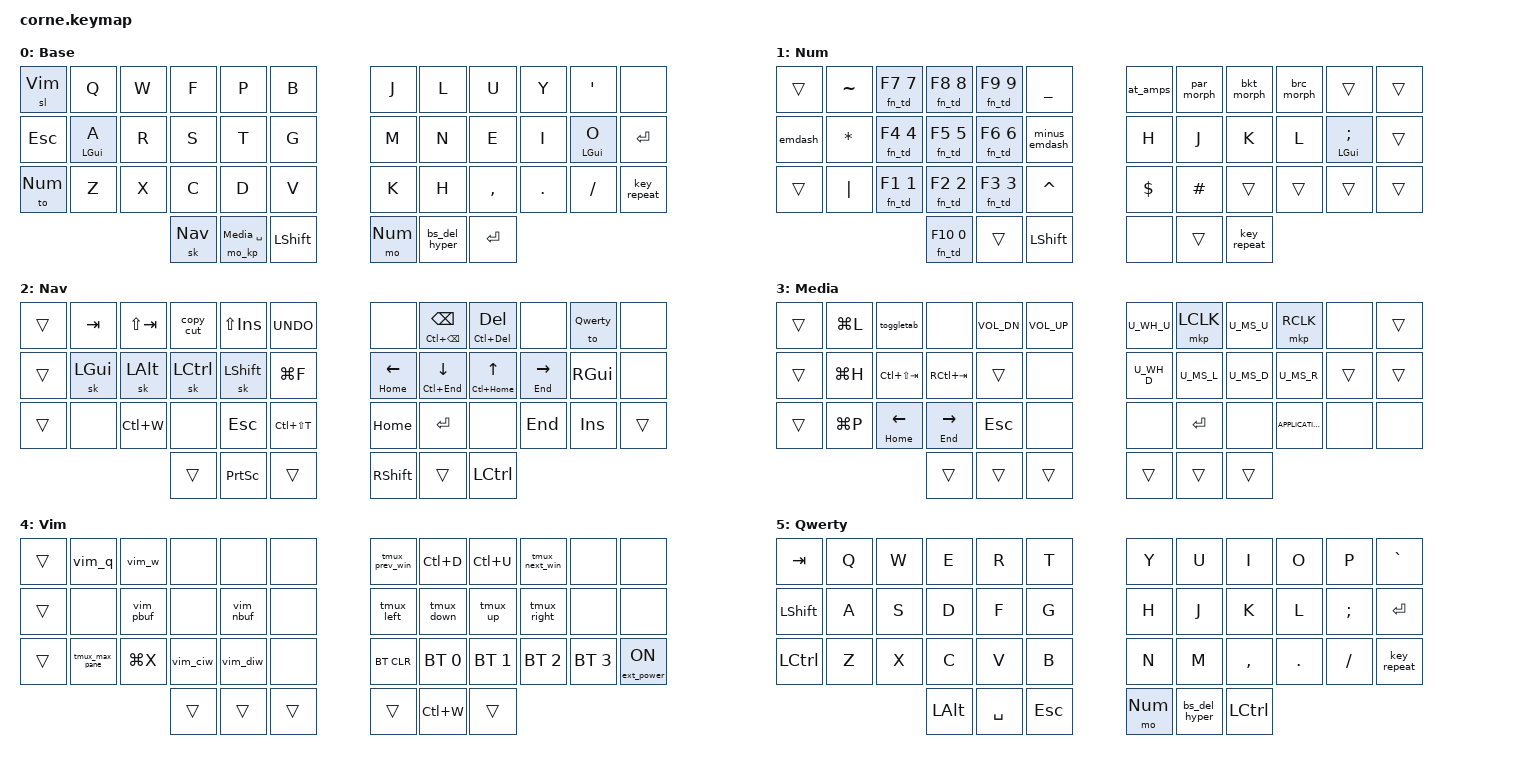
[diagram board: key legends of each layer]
#include <behaviors.dtsi>
#include <dt-bindings/zmk/keys.h>
#include <dt-bindings/zmk/bt.h>
#include <dt-bindings/zmk/mouse.h>
#include <dt-bindings/zmk/ext_power.h>
#include <dt-bindings/zmk/outputs.h>

#include "../zmk-nodefree-config/keypos_def/keypos_42keys.h"
#include "../zmk-nodefree-config/helper.h"

#define Base 0
#define Num 1
#define Nav 2
#define Media 3
#define Vim 4
#define Qwerty 5

#include "combos.dtsi"  // must be sourced after layer-shortcuts
#include "mouse.dtsi"

#define QUICK_TAP_MS 175

&sk {  // sticky-key config
    release-after-ms = <600>;  // release after 0.6s
    quick-release;             // no double capitalization when rolling keys
};

&sl {  // sticky-layer config
    ignore-modifiers;
};

&mt {
    flavor = "tap-preferred";
    tapping-term-ms = <220>;
    quick-tap-ms = <220>;              // repeat on tap-into-hold
    hold-trigger-key-positions = <0>;  // tap on interrupt
};

#define NAV_LEFT  &mt HOME     LEFT    // tap: left  | long-tap: beginning of line
#define NAV_RIGHT &mt END      RIGHT   // tap: right | long-tap: end       of line
#define NAV_UP    &mt LC(HOME) UP      // tap: up    | long-tap: beginning of document
#define NAV_DOWN  &mt LC(END)  DOWN    // tap: down  | long-tap: end       of document
#define NAV_BSPC  &mt LC(BSPC) BSPC    // tap: bspc  | long-tap: delete word backward
#define NAV_DEL   &mt LC(DEL)  DEL     // tap: del   | long-tap: delete word forward

&lt {
    flavor = "balanced";
    tapping-term-ms = <200>;
    quick_tap_ms = <QUICK_TAP_MS>;
};

&caps_word {  // mods deactivate caps-word, requires PR #1441
    /delete-property/ ignore-modifiers;
};


/* Homerow mods */

#define KEYS_L LT0 LT1 LT2 LT3 LT4 LM0 LM1 LM2 LM3 LM4 LB0 LB1 LB2 LB3 LB4  // left-hand keys
#define KEYS_R RT0 RT1 RT2 RT3 RT4 RM0 RM1 RM2 RM3 RM4 RB0 RB1 RB2 RB3 RB4  // right-hand keys
#define THUMBS LH2 LH1 LH0 RH0 RH1 RH2                                      // thumb keys

ZMK_BEHAVIOR(hml, hold_tap,  // left-hand HRMs
    flavor = "balanced";
    tapping-term-ms = <280>;
    quick-tap-ms = <QUICK_TAP_MS>;
    require-prior-idle-ms = <150>;
    bindings = <&kp>, <&kp>;
    hold-trigger-key-positions = <KEYS_R THUMBS>;
    hold-trigger-on-release;            // requires PR #1423
)

ZMK_BEHAVIOR(hmr, hold_tap,  // right-hand HRMs
    flavor = "balanced";
    tapping-term-ms = <280>;
    quick-tap-ms = <QUICK_TAP_MS>;
    bindings = <&kp>, <&kp>;
    require-prior-idle-ms = <150>;
    hold-trigger-key-positions = <KEYS_L THUMBS>;
    hold-trigger-on-release;            // requires PR #1423
)

ZMK_BEHAVIOR(fn_td, hold_tap,  // right-hand HRMs
    flavor = "tap-preferred";
    tapping-term-ms = <300>;
    quick-tap-ms = <0>;
    bindings = <&kp>, <&kp>;
)

// tap: backspace | lshft + tap: delete | rshft + tap: shift-delete | hold: hyper
ZMK_BEHAVIOR(bs_del_hyper, mod_morph,
    bindings = <&kp BSPC>, <&kp DEL>;
    mods = <(MOD_LSFT|MOD_RSFT)>;
    keep-mods = <RSHIFT>;  // requires PR #1412
)

ZMK_BEHAVIOR(emdash, macro,
    wait-ms = <0>;
    tap-ms = <100>;
    bindings = <&kp RALT &kp MINUS &kp MINUS &kp MINUS>;
)

ZMK_BEHAVIOR(minus_emdash, mod_morph,
    bindings = <&kp MINUS>, <&emdash>;
    mods = <(MOD_LSFT|MOD_RSFT)>;
)

// tap: copy | double-tap: cut
ZMK_BEHAVIOR(copy_cut, tap_dance,
    tapping-term-ms = <200>;
    bindings = <&kp LC(INS)>, <&kp LC(X)>;
)

ZMK_BEHAVIOR(mo_kp, hold_tap,
    flavor = "balanced";
    tapping-term-ms = <200>;
    quick-tap-ms = <QUICK_TAP_MS>;
    bindings = <&mo>, <&kp>;
)

// brackets mod
ZMK_BEHAVIOR(par_morph, mod_morph,
    bindings = <&kp LPAR>, <&kp RPAR>;
    mods = <(MOD_LSFT|MOD_RSFT)>;
)

ZMK_BEHAVIOR(bkt_morph, mod_morph,
    bindings = <&kp LBKT>, <&kp RBKT>;
    mods = <(MOD_LSFT|MOD_RSFT)>;
)

ZMK_BEHAVIOR(brc_morph, mod_morph,
    bindings = <&kp LBRC>, <&kp RBRC>;
    mods = <(MOD_LSFT|MOD_RSFT)>;
)

// vim: change inner word
ZMK_BEHAVIOR(ciw, macro,
    wait-ms = <0>;
    tap-ms = <5>;
    bindings = <&kp C &kp I &kp W>;
)
ZMK_BEHAVIOR(ciwc, macro,
    wait-ms = <0>;
    tap-ms = <5>;
    bindings = <&kp C &kp I &kp LS(W)>;
)
ZMK_BEHAVIOR(vim_ciw, tap_dance,
    tapping-term-ms = <200>;
    bindings = <&ciw>, <&ciwc>;
)

// vim: delete inner word
ZMK_BEHAVIOR(diw, macro,
    wait-ms = <0>;
    tap-ms = <5>;
    bindings = <&kp ESC &kp D &kp I &kp W>;
)
ZMK_BEHAVIOR(diwc, macro,
    wait-ms = <0>;
    tap-ms = <5>;
    bindings = <&kp ESC &kp D &kp I &kp LS(W)>;
)
ZMK_BEHAVIOR(vim_diw, tap_dance,
    tapping-term-ms = <200>;
    bindings = <&diw>, <&diwc>;
)

ZMK_BEHAVIOR(vim_q, macro,
    wait-ms = <0>;
    tap-ms = <5>;
    bindings = <&kp ESC &kp COLON &kp Q &kp EXCL &kp RET>;
)

ZMK_BEHAVIOR(vim_w, macro,
    wait-ms = <0>;
    tap-ms = <5>;
    bindings = <&kp ESC &kp COLON &kp W &kp Q &kp EXCL &kp RET>;
)

ZMK_BEHAVIOR(vim_pbuf, macro,
    wait-ms = <0>;
    tap-ms = <5>;
    bindings = <&kp ESC &kp COLON &kp B &kp P &kp R &kp E &kp V &kp I &kp O &kp U &kp S &kp RET>;
)

ZMK_BEHAVIOR(vim_nbuf, macro,
    wait-ms = <0>;
    tap-ms = <5>;
    bindings = <&kp ESC &kp COLON &kp B &kp N &kp E &kp X &kp T &kp RET>;
)

// ^ to toggle tab in firefox via vimium
ZMK_BEHAVIOR(toggletab, macro,
    wait-ms = <0>;
    tap-ms = <5>;
    bindings = <&kp TAB &kp LS(TAB) &kp CARET>;
)


// tmux pane navigation
ZMK_BEHAVIOR(tmux_left, macro,
    wait-ms = <0>;
    tap-ms = <5>;
    bindings = <&kp LC(A) &kp H>;
)

ZMK_BEHAVIOR(tmux_right, macro,
    wait-ms = <0>;
    tap-ms = <5>;
    bindings = <&kp LC(A) &kp L>;
)

ZMK_BEHAVIOR(tmux_up, macro,
    wait-ms = <0>;
    tap-ms = <5>;
    bindings = <&kp LC(A) &kp K>;
)

ZMK_BEHAVIOR(tmux_down, macro,
    wait-ms = <0>;
    tap-ms = <5>;
    bindings = <&kp LC(A) &kp J>;
)

ZMK_BEHAVIOR(tmux_prev_win, macro,
    wait-ms = <0>;
    tap-ms = <5>;
    bindings = <&kp LC(A) &kp P>;
)

ZMK_BEHAVIOR(tmux_next_win, macro,
    wait-ms = <0>;
    tap-ms = <5>;
    bindings = <&kp LC(A) &kp N>;
)

ZMK_BEHAVIOR(tmux_max_pane, macro,
    wait-ms = <0>;
    tap-ms = <5>;
    bindings = <&kp LC(A) &kp Z>;
)

ZMK_BEHAVIOR(par_td, tap_dance,
    tapping-term-ms = <200>;
    bindings = <&kp LPAR>, <&kp RPAR>;
)
ZMK_BEHAVIOR(bkt_td, tap_dance,
    tapping-term-ms = <200>;
    bindings = <&kp LBKT>, <&kp RBKT>;
)
ZMK_BEHAVIOR(brc_td, tap_dance,
    tapping-term-ms = <300>;
    bindings = <&kp LBRC>, <&kp RBRC>;
)
ZMK_BEHAVIOR(lt_gt, tap_dance,
    tapping-term-ms = <200>;
    bindings = <&kp LT>, <&kp GT>;
)
ZMK_BEHAVIOR(at_amps, tap_dance,
    tapping-term-ms = <200>;
    bindings = <&kp AT>, <&kp AMPS>;
)


/ {
    keymap {
        compatible = "zmk,keymap";

        default_layer {
          display-name = "Base";
            bindings = <
            &sl Vim      &kp Q                &kp W         &kp F           &kp P             &kp B         &kp J      &kp L           &kp U         &kp Y        &kp APOS       &none
            &kp ESC      &hml LGUI A          &kp R         &kp S           &kp T             &kp G         &kp M      &kp N   &kp E  &kp I  &hmr LGUI O    &kp ENTER
            &to Num      &kp Z                &kp X         &kp C           &kp D             &kp V         &kp K      &kp H           &kp COMMA     &kp DOT      &kp FSLH       &key_repeat
                                                            &sk Nav   &mo_kp Media SPACE   &kp LSHIFT        &mo Num   &bs_del_hyper &kp ENTER
        >;
        };
        num_layer {
            display-name = "Num";
            bindings = <
            &trans   &kp TILDE     &fn_td F7 N7   &fn_td F8 N8   &fn_td F9 N9   &kp UNDER             &at_amps    &par_morph    &bkt_morph    &brc_morph       &trans           &trans
            &emdash   &kp STAR      &fn_td F4 N4   &fn_td F5 N5   &fn_td F6 N6   &minus_emdash             &kp H       &kp J      &kp K      &kp L   &hmr LGUI SEMI    &trans
            &trans   &kp PIPE      &fn_td F1 N1   &fn_td F2 N2   &fn_td F3 N3   &kp CARET             &kp DLLR    &kp HASH   &trans     &trans        &trans           &trans
                                                  &fn_td F10 N0    &trans       &kp LSHIFT                &none       &trans     &key_repeat
        >;
        };
        nav_layer {
            display-name = "Nav";
            bindings = <
            &trans       &kp TAB   &kp LS(TAB) &copy_cut        &kp LS(INS)   &kp K_UNDO           &none      NAV_BSPC    NAV_DEL      &none      &to Qwerty   &none
            &trans       &sk LGUI  &sk LALT    &sk LCTRL        &sk LSHIFT    &kp LG(F)            NAV_LEFT   NAV_DOWN    NAV_UP       NAV_RIGHT  &kp RGUI   &none
            &trans       &none    &kp LC(W)    &none   &kp ESC   &kp LC(LS(T))                     &kp HOME   &kp ENTER   &none    &kp END    &kp INS        &trans
                                               &trans           &kp PSCRN      &trans              &kp RSHIFT     &trans      &kp LCTRL
        >;
        };
        media_layer {
            display-name = "Media";
            bindings = <
            &trans   &kp LG(L)   &toggletab  &none            &kp K_VOL_DN    &kp K_VOL_UP         U_WH_U      &mkp LCLK       U_MS_U    &mkp RCLK           &none    &trans
            &trans   &kp LG(H)   &kp LC(LS(TAB))  &kp RC(TAB)     &trans     &none                  U_WH_D      U_MS_L          U_MS_D    U_MS_R              &trans              &trans
            &trans   &kp LG(P)    NAV_LEFT    NAV_RIGHT    &kp ESC     &none            &none       &kp ENTER       &none     &kp K_APPLICATION   &none               &none
                                             &trans           &trans          &trans               &trans      &trans          &trans
        >;
        };
        vim_layer {
            display-name = "Vim";
            bindings = <
            &trans   &vim_q          &vim_w       &none       &none       &none           &tmux_prev_win  &kp LC(D)    &kp LC(U)  &tmux_next_win   &none   &none
            &trans   &none           &vim_pbuf      &none       &vim_nbuf       &none           &tmux_left      &tmux_down   &tmux_up   &tmux_right     &none      &none
            &trans   &tmux_max_pane  &kp LG(X)   &vim_ciw    &vim_diw    &none           &bt BT_CLR          &bt BT_SEL 0    &bt BT_SEL 1    &bt BT_SEL 2      &bt BT_SEL 3        &ext_power EP_ON
                                               &trans     &trans      &trans          &trans        &kp LC(W)         &trans
        >;
        };
        qwerty_layer {
          display-name = "Qwerty";
            bindings = <
            &kp TAB     &kp Q         &kp W         &kp E           &kp R             &kp T                 &kp Y      &kp U      &kp I         &kp O        &kp P       &kp GRAVE
            &kp LSHIFT    &kp A         &kp S         &kp D           &kp F             &kp G                 &kp H      &kp J      &kp K         &kp L        &kp SEMI    &kp ENTER
            &kp LCTRL    &kp Z         &kp X         &kp C           &kp V             &kp B                 &kp N      &kp M      &kp COMMA     &kp DOT      &kp FSLH    &key_repeat
            &kp LALT    &kp SPACE   &kp ESC            &mo Num    &bs_del_hyper   &kp LCTRL
        >;
        };
    };
};
